# MDR32F23QI register map
Vendor: Milandr; File version: 1.0
CPU: CM0 r0p0, little endian, no MPU, no FPU, 2 interrupt priority bits
Registers are 32-bit, read-write, reset 0x0 unless marked. A register's access mark holds for its fields unless they carry their own. Offsets are from the block's base; lines under a group give offsets from that group; [hi:lo] are bit positions; {n}, {i} and the like mark numbered series; 'fields as' and 'values as' point back to an identical list; <NAME> marks a mode.

## Memory map
0x40000000 MDR_SSP size 0x1000 — SSP
0x40008000 MDR_UART0 size 0x1000 — UART0 interface controller registers
0x40010000 MDR_UART1 size 0x1000 — UART1 interface controller registers
0x40018000 MDR_EEPROM size 0x1000 — Flash programm memory interface controller registers
0x40020000 MDR_RST_CLK size 0x1000 — RST_CLK
0x40030000 MDR_I2C size 0x1000 — I2C interface controller registers
0x40038000 MDR_LCD size 0x24 — LCD Display Controler
0x40040000 MDR_ADC size 0x1000 — ADC
0x40048000 MDR_WWDG size 0x1000 — WWDG
0x40050000 MDR_IWDG size 0x1000 — IWDG
0x40058000 MDR_POWER size 0x1000 — POWER
0x40060000 MDR_BKP size 0x1000 — BKP
0x40068000 MDR_ADCUI size 0x124 — Energy Counter Block
0x40070000 MDR_TIMER0 size 0x1000 — TIMER0
0x40078000 MDR_TIMER1 size 0x1000 — TIMER1
0x40080000 MDR_PORTA size 0x1000 — PORTA
0x40088000 MDR_PORTB size 0x1000 — PORTB
0x40090000 MDR_PORTC size 0x1000 — PORTC

## Interrupts
1 UART0_IRQ (MDR_UART0)
2 UART1_IRQ (MDR_UART1)
3 SSP1_IRQ (MDR_SSP)
4 POWER_IRQ (MDR_POWER)
5 WWDG_IRQ (MDR_WWDG)
6 TIMER0_IRQ (MDR_TIMER0)
7 TIMER1_IRQ (MDR_TIMER1)
8 ADC_IRQ (MDR_ADC)
9 I2C_IRQ (MDR_I2C)
10 BKP_RTC_IRQ (MDR_BKP)
11 EXT_INT0_IRQ (MDR_PORTC)
12 EXT_INT1_IRQ (MDR_PORTC)
13 EXT_INT2_IRQ (MDR_PORTC)
14 ADCUI_IRQ (MDR_ADCUI)

## MDR_SSP — SSP
Base 0x40000000
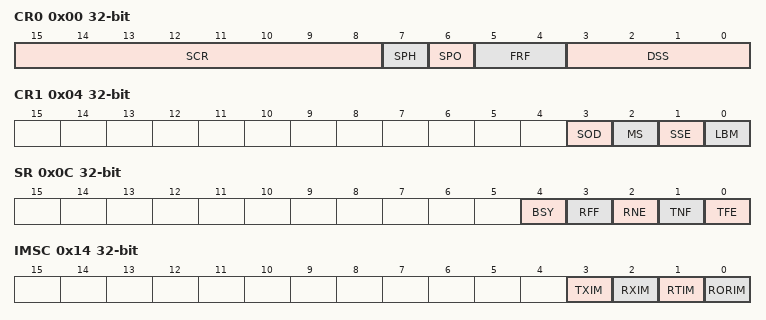
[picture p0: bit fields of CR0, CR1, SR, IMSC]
0x00 CR0 — SSP Control0 Register
  [15:8] SCR, [7] SPH, [6] SPO, [5:4] FRF, [3:0] DSS
0x04 CR1 — SSP Control1 Register
  [3] SOD, [2] MS, [1] SSE, [0] LBM
0x08 DR wo — SSP Data Register
  [15:0] DATA
0x0C SR — SSP Status Register
  [4] BSY, [3] RFF, [2] RNE, [1] TNF, [0] TFE
0x10 CPSR — SSP Clock Prescaler Register
  [7:0] CPSDVSR
0x14 IMSC — SSP Interrupt Mask Register
  [3] TXIM, [2] RXIM, [1] RTIM, [0] RORIM
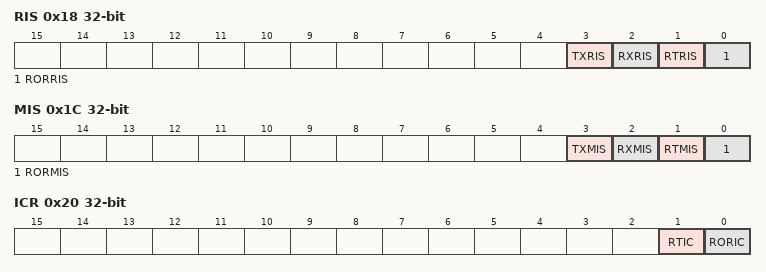
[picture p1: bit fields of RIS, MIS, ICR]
0x18 RIS — SSP Interrupt Pending Register
  [3] TXRIS, [2] RXRIS, [1] RTRIS, [0] RORRIS
0x1C MIS — SSP Masked Interrupt Pending Register
  [3] TXMIS, [2] RXMIS, [1] RTMIS, [0] RORMIS
0x20 ICR — SSP Interrupt Clear Register
  [1] RTIC, [0] RORIC

## MDR_UART0 — UART0 interface controller registers
Base 0x40008000
Same registers: MDR_UART1 0x40010000
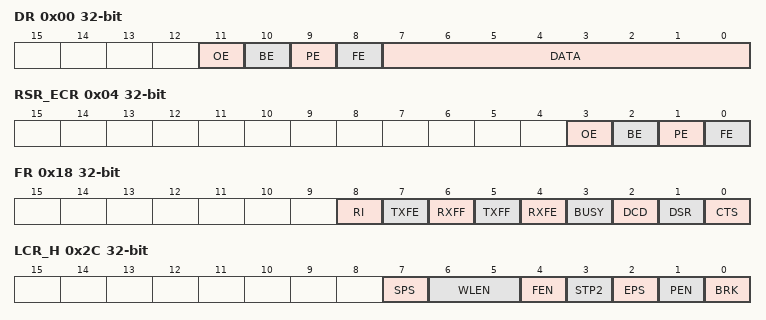
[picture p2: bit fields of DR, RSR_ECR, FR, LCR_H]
0x00 DR wo — UART Data Register
  [11] OE, [10] BE, [9] PE, [8] FE, [7:0] DATA
0x04 RSR_ECR — UART RSR Register
  [3] OE, [2] BE, [1] PE, [0] FE
0x18 FR — UART Flag Register
  [8] RI, [7] TXFE, [6] RXFF, [5] TXFF, [4] RXFE, [3] BUSY, [2] DCD, [1] DSR, [0] CTS
0x20 ILPR
  [7:0] ILPDVSR
0x24 IBRD
  [15:0] BAUD_DIVINT
0x28 FBRD
  [5:0] BAUD_DIVFRAC
0x2C LCR_H — UART LCR_H Register
  [7] SPS, [6:5] WLEN, [4] FEN, [3] STP2, [2] EPS, [1] PEN, [0] BRK
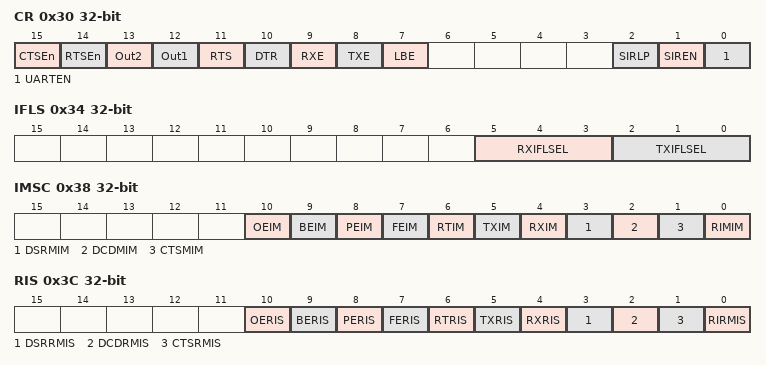
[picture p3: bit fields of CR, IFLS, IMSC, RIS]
0x30 CR — UART Command Register
  [15] CTSEn, [14] RTSEn, [13] Out2, [12] Out1, [11] RTS, [10] DTR, [9] RXE, [8] TXE, [7] LBE, [2] SIRLP, [1] SIREN, [0] UARTEN
0x34 IFLS — UART IFLS Register
  [5:3] RXIFLSEL, [2:0] TXIFLSEL
0x38 IMSC — UART Interrupt Mask Register
  [10] OEIM, [9] BEIM, [8] PEIM, [7] FEIM, [6] RTIM, [5] TXIM, [4] RXIM, [3] DSRMIM, [2] DCDMIM, [1] CTSMIM, [0] RIMIM
0x3C RIS — UART Interrupt Pending Register
  [10] OERIS, [9] BERIS, [8] PERIS, [7] FERIS, [6] RTRIS, [5] TXRIS, [4] RXRIS, [3] DSRRMIS, [2] DCDRMIS, [1] CTSRMIS, [0] RIRMIS
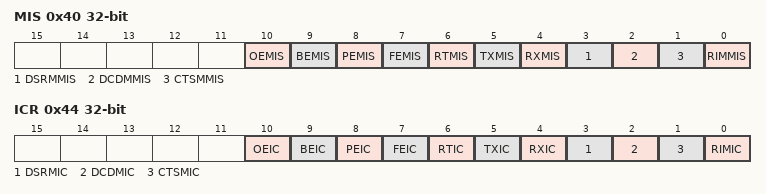
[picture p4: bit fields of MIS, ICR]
0x40 MIS — UART Masked Interrupt Pending Register
  [10] OEMIS, [9] BEMIS, [8] PEMIS, [7] FEMIS, [6] RTMIS, [5] TXMIS, [4] RXMIS, [3] DSRMMIS, [2] DCDMMIS, [1] CTSMMIS, [0] RIMMIS
0x44 ICR — UART Interrupt Clear Register
  [10] OEIC, [9] BEIC, [8] PEIC, [7] FEIC, [6] RTIC, [5] TXIC, [4] RXIC, [3] DSRMIC, [2] DCDMIC, [1] CTSMIC, [0] RIMIC

## MDR_EEPROM — Flash programm memory interface controller registers
Base 0x40018000
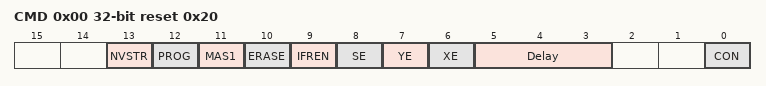
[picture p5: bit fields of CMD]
0x00 CMD reset 0x20 — EEPROM Command Register
  [13] NVSTR, [12] PROG, [11] MAS1, [10] ERASE, [9] IFREN, [8] SE, [7] YE, [6] XE, [5:3] Delay, [0] CON
0x04 ADR — EEPROM Address Register
0x08 DI — EEPROM Read Data Register
  [31:0] DATA
0x0C DO — EEPROM Write Data Register
  [31:0] DATA
0x10 KEY — EEPROM Key Register
